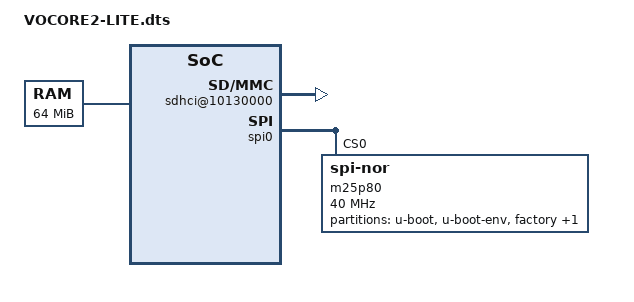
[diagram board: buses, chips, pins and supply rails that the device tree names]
/dts-v1/;

#include "VOCORE2.dtsi"

/ {
	memory@0 {
		device_type = "memory";
		reg = <0x0 0x4000000>;
	};
	sdhci@10130000 {
		mediatek,cd-poll;
		status = "okay";
	};
};

&spi0 {
	status = "okay";

	m25p80@0 {
		#address-cells = <1>;
		#size-cells = <1>;
		compatible = "jedec,spi-nor";
		reg = <0>;
		linux,modalias = "m25p80";
		spi-max-frequency = <40000000>;
		m25p,chunked-io = <32>;

		partition@0 {
			label = "u-boot";
			reg = <0x0 0x30000>;
			read-only;
		};

		partition@30000 {
			label = "u-boot-env";
			reg = <0x30000 0x10000>;
		};

		factory: partition@40000 {
			label = "factory";
			reg = <0x40000 0x10000>;
			read-only;
		};

		partition@50000 {
			label = "firmware";
			reg = <0x50000 0x7b0000>;
		};
	};
};

